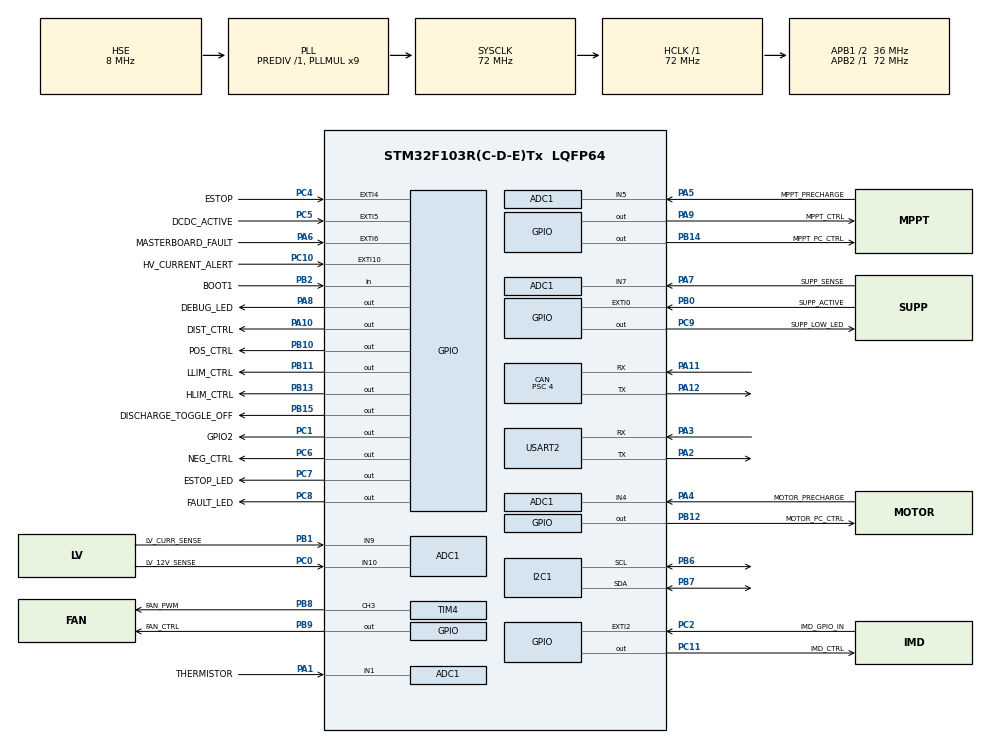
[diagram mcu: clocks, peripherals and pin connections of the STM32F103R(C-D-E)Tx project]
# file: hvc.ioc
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ADC1.Channel-0\#ChannelRegularConversion=ADC_CHANNEL_1
ADC1.Channel-1\#ChannelRegularConversion=ADC_CHANNEL_4
ADC1.Channel-2\#ChannelRegularConversion=ADC_CHANNEL_5
ADC1.Channel-3\#ChannelRegularConversion=ADC_CHANNEL_7
ADC1.Channel-4\#ChannelRegularConversion=ADC_CHANNEL_9
ADC1.Channel-5\#ChannelRegularConversion=ADC_CHANNEL_10
ADC1.ContinuousConvMode=DISABLE
ADC1.ExternalTrigConv=ADC_EXTERNALTRIGCONV_T3_TRGO
ADC1.NbrOfConversion=6
ADC1.NbrOfConversionFlag=1
ADC1.Rank-0\#ChannelRegularConversion=1
ADC1.Rank-1\#ChannelRegularConversion=2
ADC1.Rank-2\#ChannelRegularConversion=3
ADC1.Rank-3\#ChannelRegularConversion=4
ADC1.Rank-4\#ChannelRegularConversion=5
ADC1.Rank-5\#ChannelRegularConversion=6
ADC1.SamplingTime-0\#ChannelRegularConversion=ADC_SAMPLETIME_7CYCLES_5
ADC1.SamplingTime-1\#ChannelRegularConversion=ADC_SAMPLETIME_7CYCLES_5
ADC1.SamplingTime-2\#ChannelRegularConversion=ADC_SAMPLETIME_7CYCLES_5
ADC1.SamplingTime-3\#ChannelRegularConversion=ADC_SAMPLETIME_7CYCLES_5
ADC1.SamplingTime-4\#ChannelRegularConversion=ADC_SAMPLETIME_7CYCLES_5
ADC1.SamplingTime-5\#ChannelRegularConversion=ADC_SAMPLETIME_7CYCLES_5
ADC1.master=1
CAN.BS1=CAN_BS1_15TQ
CAN.BS2=CAN_BS2_2TQ
CAN.CalculateBaudRate=500000
CAN.CalculateTimeBit=2000
CAN.CalculateTimeQuantum=111.11111111111111
CAN.Prescaler=4
Dma.ADC1.1.Direction=DMA_PERIPH_TO_MEMORY
Dma.ADC1.1.Instance=DMA1_Channel1
Dma.ADC1.1.MemDataAlignment=DMA_MDATAALIGN_HALFWORD
Dma.ADC1.1.MemInc=DMA_MINC_ENABLE
Dma.ADC1.1.Mode=DMA_CIRCULAR
Dma.ADC1.1.PeriphDataAlignment=DMA_PDATAALIGN_HALFWORD
Dma.ADC1.1.PeriphInc=DMA_PINC_DISABLE
Dma.ADC1.1.Priority=DMA_PRIORITY_LOW
Dma.Request0=USART2_TX
Dma.Request1=ADC1
Dma.USART2_TX.0.Direction=DMA_MEMORY_TO_PERIPH
Dma.USART2_TX.0.Instance=DMA1_Channel7
Dma.USART2_TX.0.MemDataAlignment=DMA_MDATAALIGN_BYTE
Dma.USART2_TX.0.MemInc=DMA_MINC_ENABLE
Dma.USART2_TX.0.Mode=DMA_NORMAL
Dma.USART2_TX.0.PeriphDataAlignment=DMA_PDATAALIGN_BYTE
Dma.USART2_TX.0.PeriphInc=DMA_PINC_DISABLE
Dma.USART2_TX.0.Priority=DMA_PRIORITY_LOW
IWDG.Prescaler=IWDG_PRESCALER_32
IWDG.Reload=1250
Mcu.Family=STM32F1
Mcu.Name=STM32F103R(C-D-E)Tx
Mcu.Package=LQFP64
NVIC.CAN1_RX1_IRQn=true\:0\:0\:false\:false\:true\:true\:true\:true
NVIC.DMA1_Channel1_IRQn=true\:0\:0\:false\:false\:true\:false\:true\:true
NVIC.DMA1_Channel7_IRQn=true\:0\:0\:false\:false\:true\:false\:true\:true
NVIC.EXTI0_IRQn=true\:1\:0\:true\:false\:true\:true\:true\:true
NVIC.EXTI15_10_IRQn=true\:1\:0\:true\:false\:true\:true\:true\:true
NVIC.EXTI2_IRQn=true\:1\:0\:true\:false\:true\:true\:true\:true
NVIC.EXTI4_IRQn=true\:1\:0\:true\:false\:true\:true\:true\:true
NVIC.EXTI9_5_IRQn=true\:1\:0\:true\:false\:true\:true\:true\:true
NVIC.I2C1_ER_IRQn=true\:0\:0\:false\:false\:true\:true\:true\:true
NVIC.I2C1_EV_IRQn=true\:0\:0\:false\:false\:true\:true\:true\:true
NVIC.PriorityGroup=NVIC_PRIORITYGROUP_4
NVIC.USART2_IRQn=true\:0\:0\:false\:false\:true\:true\:true\:true
NVIC.USB_HP_CAN1_TX_IRQn=true\:0\:0\:false\:false\:true\:true\:true\:true
NVIC.USB_LP_CAN1_RX0_IRQn=true\:0\:0\:false\:false\:true\:true\:true\:true
PA1.GPIO_Label=THERMISTOR
PA1.Signal=ADCx_IN1
PA10.GPIO_Label=DIST_CTRL
PA10.Signal=GPIO_Output
PA11.Mode=CAN_Activate
PA11.Signal=CAN_RX
PA12.Mode=CAN_Activate
PA12.Signal=CAN_TX
PA13.Mode=Trace_Asynchronous_SW
PA13.Signal=SYS_JTMS-SWDIO
PA14.Mode=Trace_Asynchronous_SW
PA14.Signal=SYS_JTCK-SWCLK
PA2.Mode=Asynchronous
PA2.Signal=USART2_TX
PA3.Mode=Asynchronous
PA3.Signal=USART2_RX
PA4.GPIO_Label=MOTOR_PRECHARGE
PA4.Signal=ADCx_IN4
PA5.GPIO_Label=MPPT_PRECHARGE
PA5.Signal=ADCx_IN5
PA6.GPIO_Label=MASTERBOARD_FAULT
PA6.GPIO_ModeDefaultEXTI=GPIO_MODE_IT_RISING_FALLING
PA6.Signal=GPXTI6
PA7.GPIO_Label=SUPP_SENSE
PA7.Signal=ADCx_IN7
PA8.GPIO_Label=DEBUG_LED
PA8.Signal=GPIO_Output
PA9.GPIO_Label=MPPT_CTRL
PA9.Signal=GPIO_Output
PB0.GPIO_Label=SUPP_ACTIVE
PB0.GPIO_ModeDefaultEXTI=GPIO_MODE_IT_RISING_FALLING
PB0.Signal=GPXTI0
PB1.GPIO_Label=LV_CURR_SENSE
PB1.Signal=ADCx_IN9
PB10.GPIO_Label=POS_CTRL
PB10.Signal=GPIO_Output
PB11.GPIO_Label=LLIM_CTRL
PB11.Signal=GPIO_Output
PB12.GPIO_Label=MOTOR_PC_CTRL
PB12.Signal=GPIO_Output
PB13.GPIO_Label=HLIM_CTRL
PB13.Signal=GPIO_Output
PB14.GPIO_Label=MPPT_PC_CTRL
PB14.Signal=GPIO_Output
PB15.GPIO_Label=DISCHARGE_TOGGLE_OFF
PB15.Signal=GPIO_Output
PB2.GPIO_Label=BOOT1
PB2.Signal=GPIO_Input
PB3.Mode=Trace_Asynchronous_SW
PB3.Signal=SYS_JTDO-TRACESWO
PB6.Mode=I2C
PB6.Signal=I2C1_SCL
PB7.Mode=I2C
PB7.Signal=I2C1_SDA
PB8.GPIO_Label=FAN_PWM
PB8.Signal=S_TIM4_CH3
PB9.GPIO_Label=FAN_CTRL
PB9.Signal=GPIO_Output
PC0.GPIO_Label=LV_12V_SENSE
PC0.Signal=ADCx_IN10
PC1.GPIO_Label=GPIO2
PC1.Signal=GPIO_Output
PC10.GPIO_Label=HV_CURRENT_ALERT
PC10.GPIO_ModeDefaultEXTI=GPIO_MODE_IT_RISING_FALLING
PC10.Signal=GPXTI10
PC11.GPIO_Label=IMD_CTRL
PC11.Signal=GPIO_Output
PC2.GPIO_Label=IMD_GPIO_IN
PC2.GPIO_ModeDefaultEXTI=GPIO_MODE_IT_RISING_FALLING
PC2.Signal=GPXTI2
PC4.GPIO_Label=ESTOP
PC4.GPIO_ModeDefaultEXTI=GPIO_MODE_IT_RISING_FALLING
PC4.Signal=GPXTI4
PC5.GPIO_Label=DCDC_ACTIVE
PC5.GPIO_ModeDefaultEXTI=GPIO_MODE_IT_RISING_FALLING
PC5.Signal=GPXTI5
PC6.GPIO_Label=NEG_CTRL
PC6.Signal=GPIO_Output
PC7.GPIO_Label=ESTOP_LED
PC7.Signal=GPIO_Output
PC8.GPIO_Label=FAULT_LED
PC8.Signal=GPIO_Output
PC9.GPIO_Label=SUPP_LOW_LED
PC9.Signal=GPIO_Output
PD0-OSC_IN.Mode=HSE-External-Oscillator
PD0-OSC_IN.Signal=RCC_OSC_IN
PD1-OSC_OUT.Mode=HSE-External-Oscillator
PD1-OSC_OUT.Signal=RCC_OSC_OUT
ProjectManager.HeapSize=0x200
ProjectManager.StackSize=0x400
ProjectManager.TargetToolchain=CMake
RCC.ADCPresc=RCC_ADCPCLK2_DIV6
RCC.AHBFreq_Value=72000000
RCC.APB1CLKDivider=RCC_HCLK_DIV2
RCC.APB1Freq_Value=36000000
RCC.APB1TimFreq_Value=72000000
RCC.APB2Freq_Value=72000000
RCC.APB2TimFreq_Value=72000000
RCC.HCLKFreq_Value=72000000
RCC.PLLMUL=RCC_PLL_MUL9
RCC.PLLSourceVirtual=RCC_PLLSOURCE_HSE
RCC.SYSCLKFreq_VALUE=72000000
RCC.SYSCLKSource=RCC_SYSCLKSOURCE_PLLCLK
RCC.USBFreq_Value=72000000
SH.ADCx_IN1.0=ADC1_IN1,IN1
SH.ADCx_IN10.0=ADC1_IN10,IN10
SH.ADCx_IN4.0=ADC1_IN4,IN4
SH.ADCx_IN5.0=ADC1_IN5,IN5
SH.ADCx_IN7.0=ADC1_IN7,IN7
SH.ADCx_IN9.0=ADC1_IN9,IN9
SH.S_TIM4_CH3.0=TIM4_CH3,PWM Generation3 CH3
TIM3.AutoReloadPreload=TIM_AUTORELOAD_PRELOAD_ENABLE
TIM3.Period=7200-1
TIM3.Prescaler=1-1
TIM3.TIM_MasterOutputTrigger=TIM_TRGO_UPDATE
TIM4.Channel-PWM\ Generation3\ CH3=TIM_CHANNEL_3
USART2.VirtualMode=VM_ASYNC
VP_IWDG_VS_IWDG.Mode=IWDG_Activate
VP_TIM3_VS_ClockSourceINT.Mode=Internal
board=custom

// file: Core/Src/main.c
/* USER CODE BEGIN Header */
/**
 ******************************************************************************
 * @file           : main.c
 * @brief          : Main program body
 ******************************************************************************
 * @attention
 *
 * Copyright (c) 2026 STMicroelectronics.
 * All rights reserved.
 *
 * This software is licensed under terms that can be found in the LICENSE file
 * in the root directory of this software component.
 * If no LICENSE file comes with this software, it is provided AS-IS.
 *
 ******************************************************************************
 */
/* USER CODE END Header */
#include "main.h"
#include "adc.h"
#include "can.h"
#include "dma.h"
#include "i2c.h"
#include "iwdg.h"
#include "tim.h"
#include "usart.h"
#include "gpio.h"

/* USER CODE BEGIN Includes */

#include "hvc_main.h"
#include "fsm.h"

/* USER CODE END Includes */

void SystemClock_Config(void);

int main(void)
{

  /* MCU Configuration--------------------------------------------------------*/

  /* Reset of all peripherals, Initializes the Flash interface and the Systick. */
  HAL_Init();

  /* Configure the system clock */
  SystemClock_Config();

  /* USER CODE BEGIN SysInit */
  __HAL_DBGMCU_FREEZE_IWDG();
  /* USER CODE END SysInit */

  /* Initialize all configured peripherals */
  MX_GPIO_Init();
  MX_DMA_Init();
  MX_ADC1_Init();
  MX_CAN_Init();
  MX_I2C1_Init();
  MX_TIM4_Init();
  MX_USART2_UART_Init();
  MX_TIM3_Init();
  MX_IWDG_Init();
  /* USER CODE BEGIN 2 */

  HVC_Init(&huart2, &hadc1, &htim3, &htim4, &hi2c1, &hcan);

  /* USER CODE END 2 */

  /* Infinite loop */
    while (1)
    {

    /* USER CODE BEGIN 3 */

      HAL_IWDG_Refresh(&hiwdg); // every pass, in normal mode and in tests

      HVC_Main();
    }
  /* USER CODE END 3 */
}

void SystemClock_Config(void)
{
  RCC_OscInitTypeDef RCC_OscInitStruct = {0};
  RCC_ClkInitTypeDef RCC_ClkInitStruct = {0};
  RCC_PeriphCLKInitTypeDef PeriphClkInit = {0};

  /** Initializes the RCC Oscillators according to the specified parameters
  * in the RCC_OscInitTypeDef structure.
  */
  RCC_OscInitStruct.OscillatorType = RCC_OSCILLATORTYPE_LSI|RCC_OSCILLATORTYPE_HSE;
  RCC_OscInitStruct.HSEState = RCC_HSE_ON;
  RCC_OscInitStruct.HSEPredivValue = RCC_HSE_PREDIV_DIV1;
  RCC_OscInitStruct.HSIState = RCC_HSI_ON;
  RCC_OscInitStruct.LSIState = RCC_LSI_ON;
  RCC_OscInitStruct.PLL.PLLState = RCC_PLL_ON;
  RCC_OscInitStruct.PLL.PLLSource = RCC_PLLSOURCE_HSE;
  RCC_OscInitStruct.PLL.PLLMUL = RCC_PLL_MUL9;
  if (HAL_RCC_OscConfig(&RCC_OscInitStruct) != HAL_OK)
  {
    Error_Handler();
  }

  /** Initializes the CPU, AHB and APB buses clocks
  */
  RCC_ClkInitStruct.ClockType = RCC_CLOCKTYPE_HCLK|RCC_CLOCKTYPE_SYSCLK
                              |RCC_CLOCKTYPE_PCLK1|RCC_CLOCKTYPE_PCLK2;
  RCC_ClkInitStruct.SYSCLKSource = RCC_SYSCLKSOURCE_PLLCLK;
  RCC_ClkInitStruct.AHBCLKDivider = RCC_SYSCLK_DIV1;
  RCC_ClkInitStruct.APB1CLKDivider = RCC_HCLK_DIV2;
  RCC_ClkInitStruct.APB2CLKDivider = RCC_HCLK_DIV1;

  if (HAL_RCC_ClockConfig(&RCC_ClkInitStruct, FLASH_LATENCY_2) != HAL_OK)
  {
    Error_Handler();
  }
  PeriphClkInit.PeriphClockSelection = RCC_PERIPHCLK_ADC;
  PeriphClkInit.AdcClockSelection = RCC_ADCPCLK2_DIV6;
  if (HAL_RCCEx_PeriphCLKConfig(&PeriphClkInit) != HAL_OK)
  {
    Error_Handler();
  }
}

void Error_Handler(void)
{
  /* USER CODE BEGIN Error_Handler_Debug */
    /* User can add his own implementation to report the HAL error return state */
    __disable_irq();
    FSM_OpenAllContactors();
    while (1)
    {
    }
  /* USER CODE END Error_Handler_Debug */
}
